# WB32F10x register map
File version: 1.2
CPU: CM3 r2p0, little endian, MPU, no FPU, 4 interrupt priority bits
Registers are 32-bit, read-write, reset 0x0 unless marked. A register's access mark holds for its fields unless they carry their own. Offsets are from the block's base; [hi:lo] are bit positions; {n}, {i} and the like mark numbered series.

## RCC — Reset and Clock Control
Base 0x40010C00
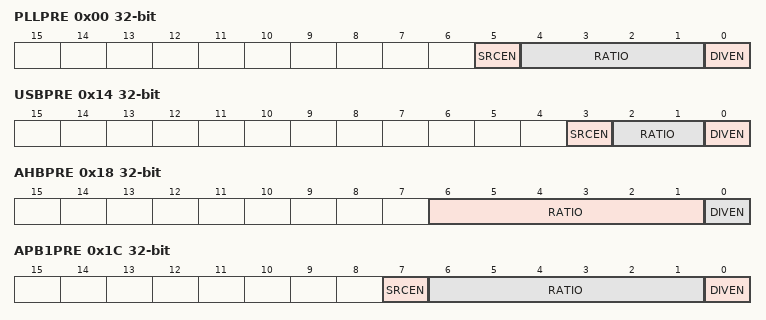
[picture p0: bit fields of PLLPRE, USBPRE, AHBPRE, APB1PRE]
0x00 PLLPRE — PLL pre-divider control register
  [5] SRCEN — PLL pre-divider input clock enable
  [4:1] RATIO — PLL ratio
  [0] DIVEN — PLL pre-divider enable
0x04 PLLSRC — PLL clock source selection register
  [0] SRC — PLL clock source selection
0x08 MAINCLKSRC — System clock source selection register
  [1:0] SRC — main clock source selection
0x0C MAINCLKUEN wo — System clock source update enable register
  [0] ENA — update main clock source
0x14 USBPRE — USB clock pre-divider control register
  [3] SRCEN — USB pre-divider input clock enable
  [2:1] RATIO — USB ratio
  [0] DIVEN — USB in clock pre-divider enable
0x18 AHBPRE — AHB clock pre-divider register
  [6:1] RATIO — AHB ratio
  [0] DIVEN — AHB pre-divider enable
0x1C APB1PRE — APB1 clock pre-divider control register
  [7] SRCEN — APB1 pre-divider input clock enable
  [6:1] RATIO — APB1 ratioo
  [0] DIVEN — APB1 pre-divider enable
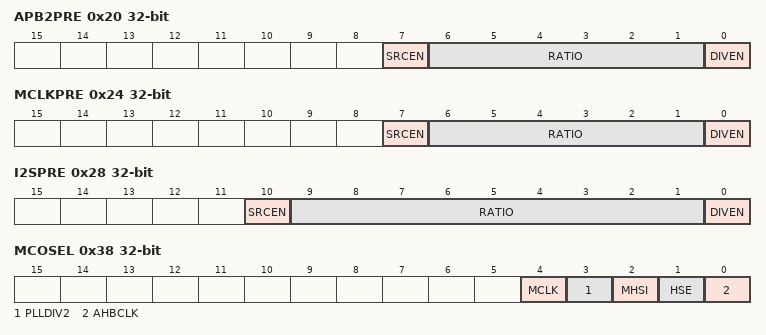
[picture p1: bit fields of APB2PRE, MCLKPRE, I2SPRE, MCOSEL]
0x20 APB2PRE — APB2 clock pre-divider control register
  [7] SRCEN — APB2 pre-divider input clock enable
  [6:1] RATIO — APB2 ratio
  [0] DIVEN — APB2 pre-divider enable
0x24 MCLKPRE — I2S MCLK clock pre-divider control register
  [7] SRCEN — I2S MCLK pre-divider input clock enable
  [6:1] RATIO — I2S clock ratio
  [0] DIVEN — I2S MCLK pre-divider enable (Divider enable)
0x28 I2SPRE — I2S SCLK clock pre-divider control register
  [10] SRCEN — I2S SCLK pre-divider input clock enable
  [9:1] RATIO — I2S sclk ratio
  [0] DIVEN — I2S SCLK pre-divider enable
0x2C MCLKSRC — I2S MCLK clock source selection register
  [0] SRC — I2S MCLK clock source selection
0x34 USBFIFOCLKSRC — USB FIFO clock source selection register
  [0] SRC — USB FIFO clock source selection
0x38 MCOSEL — Clock output selection register
  [4] MCLK — I2S MCLK output to MCO pin
  [3] PLLDIV2 — PLL clock divided by 2 output to MCO pin
  [2] MHSI — MHSI(8MHz) output to MCO pin
  [1] HSE — HSE clock output to MCO pin
  [0] AHBCLK — AHB clock output to MCO pin
0x3C AHBENR0 reset 0x7B — AHB peripherals clock enable register0
  [2] IWDGEN — IWDG clock enable control
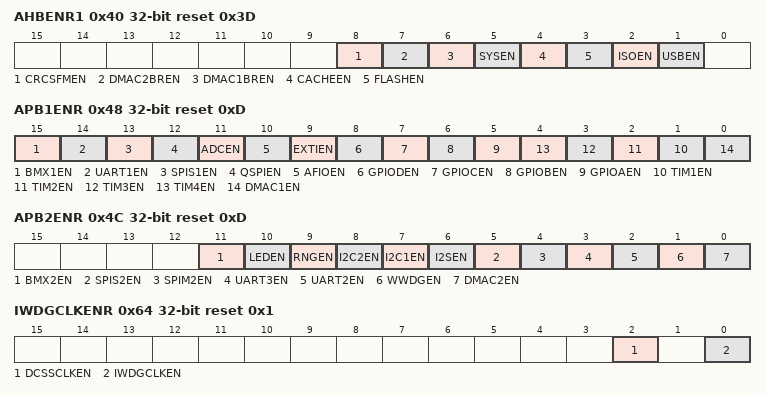
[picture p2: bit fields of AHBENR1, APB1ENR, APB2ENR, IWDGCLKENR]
0x40 AHBENR1 reset 0x3D — AHB peripherals clock enable register1
  [8] CRCSFMEN — CRC and SFM clock enable
  [7] DMAC2BREN — DMAC2-APB2 bridge clock enable
  [6] DMAC1BREN — DMAC1-APB1 bridge clock enable
  [5] SYSEN — SYS control clock enable
  [4] CACHEEN — CACHE control clock enable
  [3] FLASHEN — FLASH control clock enable
  [2] ISOEN — ISO7816 control clock enable
  [1] USBEN — USB control clock enable
0x44 AHBENR2 reset 0x3 — AHB peripherals clock enable register2
  [2] BDIEN — Battery domain interface clock enable
0x48 APB1ENR reset 0xD — APB1 peripherals clock enable register
  [15] BMX1EN — APB1 bus matrix clock enable
  [14] UART1EN — UART1 control clock enable
  [13] SPIS1EN — SPIS1 control clock enable
  [12] QSPIEN — QSPI control clock enable
  [11] ADCEN — ADC control clock enable
  [10] AFIOEN — AFIO control clock enable
  [9] EXTIEN — EXTI control clock enable
  [8] GPIODEN — GPIOD control clock enable
  [7] GPIOCEN — GPIOC control clock enable
  [6] GPIOBEN — GPIOB control clock enable
  [5] GPIOAEN — GPIOA control clock enable
  [n] TIM{n}EN (n=1..4) — TIMER{n} control clock enable
  [0] DMAC1EN — DMAC1 control clock enable
0x4C APB2ENR reset 0xD — APB2 peripherals clock enable register
  [11] BMX2EN — APB2 bus matrix clock enable
  [10] LEDEN — LED control clock enable
  [9] RNGEN — RNG control clock enable
  [8] I2C2EN — I2C2 control clock enable
  [7] I2C1EN — I2C1 control clock enable
  [6] I2SEN — I2S control clock enable
  [5] SPIS2EN — SPIS2 control clock enable
  [4] SPIM2EN — SPIM2 control clock enable
  [3] UART3EN — UART3 control clock enable
  [2] UART2EN — UART2 control clock enable
  [1] WWDGEN — WWDG clock enable
  [0] DMAC2EN — DMAC2 control clock enable
0x5C RNGCLKENR — RNG clock enable register
  [0] CLKEN — RNG clock enable
0x64 IWDGCLKENR reset 0x1 — IWDG clock enable register
  [2] DCSSCLKEN — DCSS clock enable
  [0] IWDGCLKEN — IWDG clock enable
0x6C USBCLKENR — USB48MHz clock enable register
  [0] CLKEN — USB 48MHz clock enable
0x70 I2SCLKENR — I2S SCLK clock enable register
  [0] CLKEN — I2S SCLK clock enable
0x74 SPIS1CLKENR — SPIS1 clock enable register
  [0] CLKEN — SPIS1 clock enable
0x78 SPIS2CLKENR — SPIS2 clock enable register
  [0] CLKEN — SPIS2 clock enable
0x7C USBFIFOCLKENR — USB FIFO clock enable register
  [0] CLKEN — USB FIFO clock enable
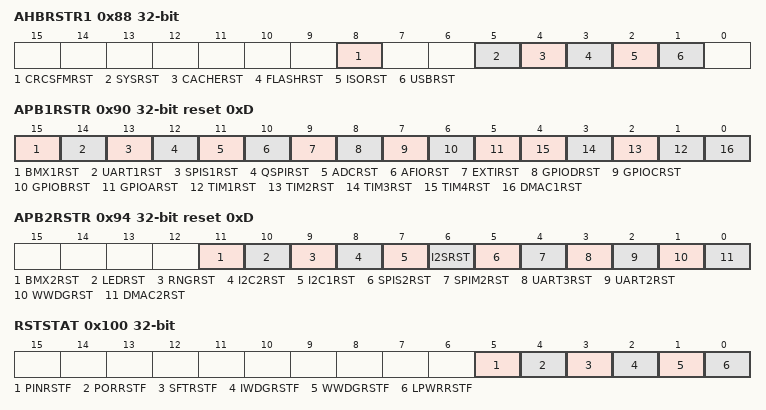
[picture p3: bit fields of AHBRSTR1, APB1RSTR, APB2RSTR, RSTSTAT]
0x88 AHBRSTR1 — AHB peripheral reset register1
  [8] CRCSFMRST — CRC and SFM reset control
  [5] SYSRST — SYS reset control
  [4] CACHERST — CACHE reset control
  [3] FLASHRST — FLASH reset control
  [2] ISORST — ISO7816 reset control
  [1] USBRST — USB reset control
0x90 APB1RSTR reset 0xD — APB1 peripheral reset register
  [15] BMX1RST — APB1 bus matrix reset control
  [14] UART1RST — UART1 reset control
  [13] SPIS1RST — SPIS1 reset control
  [12] QSPIRST — QSPI reset control
  [11] ADCRST — ADC reset control
  [10] AFIORST — AFIO reset control
  [9] EXTIRST — EXTI reset control
  [8] GPIODRST — GPIOD reset control
  [7] GPIOCRST — GPIOC reset control
  [6] GPIOBRST — GPIOB reset control
  [5] GPIOARST — GPIOA reset control
  [n] TIM{n}RST (n=1..4) — TIMER{n} reset control
  [0] DMAC1RST — DMAC1 reset control
0x94 APB2RSTR reset 0xD — APB2 peripheral reset register
  [11] BMX2RST — APB2 bus matrix reset
  [10] LEDRST — LED reset control
  [9] RNGRST — RNG reset control
  [8] I2C2RST — I2C2 reset control
  [7] I2C1RST — I2C1 reset control
  [6] I2SRST — I2S reset control
  [5] SPIS2RST — SPIS2 reset control
  [4] SPIM2RST — SPIM2 reset control
  [3] UART3RST — UART3 reset control
  [2] UART2RST — UART2 reset control
  [1] WWDGRST — WWDG reset control
  [0] DMAC2RST — DMAC2 reset control
0xB8 I2SCLKRSTR — I2S SCLK reset register
  [0] SCLKRST — I2S SCLK clock domain reset
0xC8 CLRRSTSTAT wo — Reset flag clear register
  [0] CLR — clear RCC_RSTSTAT register
0xD4 BDRSTR — Battery domain reset register
  [0] BDRST — battery domain reset
0xD8 LSI2RTCENR — LSI battery domain clock enable register
  [0] CLKEN — LSI enable for battery domain
0xDC HSE2RTCENR — HSE clock 128-divider enable register
  [0] DIVEN — 128-divider enable
0x100 RSTSTAT ro — Reset flag register
  [5] PINRSTF — set by hardware when NRST pin reset occurs
  [4] PORRSTF — set by hardware when POR/PDR reset occurs
  [3] SFTRSTF — Set by hardware when software reset occurs
  [2] IWDGRSTF — set by hardware when IWDG reset occurs in VDD domain
  [1] WWDGRSTF — Set by hardware when WWDG reset occurs
  [0] LPWRRSTF — Set by hardware when low-power reset occurs
